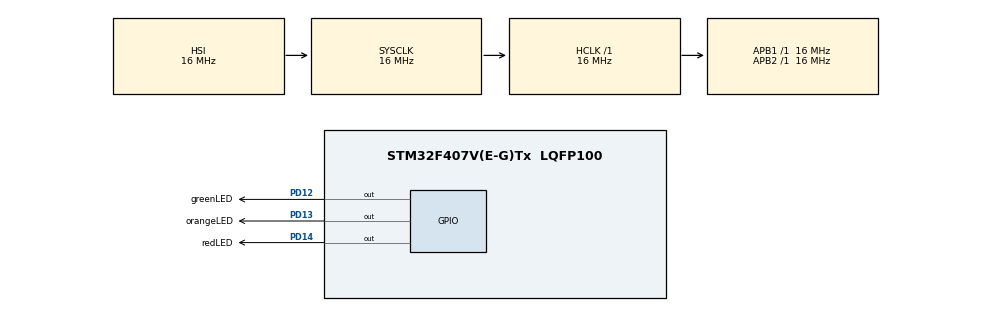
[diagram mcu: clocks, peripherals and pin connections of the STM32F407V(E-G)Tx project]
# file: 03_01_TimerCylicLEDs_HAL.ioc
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Mcu.Family=STM32F4
Mcu.Name=STM32F407V(E-G)Tx
Mcu.Package=LQFP100
NVIC.PriorityGroup=NVIC_PRIORITYGROUP_4
PD12.GPIO_Label=greenLED
PD12.Signal=GPIO_Output
PD13.GPIO_Label=orangeLED
PD13.Signal=GPIO_Output
PD14.GPIO_Label=redLED
PD14.Signal=GPIO_Output
ProjectManager.HeapSize=0x200
ProjectManager.StackSize=0x400
ProjectManager.TargetToolchain=STM32CubeIDE
RCC.AHBFreq_Value=16000000
RCC.APB1Freq_Value=16000000
RCC.APB2Freq_Value=16000000
RCC.CortexFreq_Value=16000000
RCC.HSE_VALUE=25000000
RCC.HSI_VALUE=16000000
RCC.LSE_VALUE=32768
RCC.SYSCLKFreq_VALUE=16000000
RCC.VCOOutputFreq_Value=192000000
TIM10.AutoReloadPreload=TIM_AUTORELOAD_PRELOAD_ENABLE
TIM10.Period=6000
TIM10.Prescaler=16-1
VP_TIM10_VS_ClockSourceINT.Mode=Enable_Timer
board=custom

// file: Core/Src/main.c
/* USER CODE BEGIN Header */
/**
  ******************************************************************************
  * @file           : main.c
  * @brief          : Main program body
  ******************************************************************************
  * @attention
  *
  * Copyright (c) 2024 STMicroelectronics.
  * All rights reserved.
  *
  * This software is licensed under terms that can be found in the LICENSE file
  * in the root directory of this software component.
  * If no LICENSE file comes with this software, it is provided AS-IS.
  *
  ******************************************************************************
  */
/* USER CODE END Header */
#include "main.h"

TIM_HandleTypeDef htim10;

void SystemClock_Config(void);
static void MX_GPIO_Init(void);
static void MX_TIM10_Init(void);
/* USER CODE BEGIN PFP */

void TimerReset(void);
int IsTimeUp(void);
void TimerInit(unsigned short first_durr) ;
/* USER CODE END PFP */

int main(void)
{

  /* USER CODE BEGIN 1 */
	uint8_t state =0;
  /* USER CODE END 1 */

  /* MCU Configuration--------------------------------------------------------*/

  /* Reset of all peripherals, Initializes the Flash interface and the Systick. */
  HAL_Init();

  /* Configure the system clock */
  SystemClock_Config();

  /* Initialize all configured peripherals */
  MX_GPIO_Init();
  MX_TIM10_Init();
  /* USER CODE BEGIN 2 */
  TimerInit(500);
  TimerReset();
  /* USER CODE END 2 */

  /* Infinite loop */
  /* USER CODE BEGIN WHILE */
  while (1)
  {
	  if(IsTimeUp())  //If the end of the durration for
	  {    //the current state was reached
	   TimerReset();

	   switch(state) //display the current state
	   {
	    case 0:
	    	HAL_GPIO_WritePin(greenLED_GPIO_Port, greenLED_Pin, 1);
	    	HAL_GPIO_WritePin(orangeLED_GPIO_Port, orangeLED_Pin, 0);
	    	HAL_GPIO_WritePin(redLED_GPIO_Port, redLED_Pin, 0);
	    	break;
	    case 1:
	    	HAL_GPIO_WritePin(greenLED_GPIO_Port, greenLED_Pin, 0);
	    	HAL_GPIO_WritePin(orangeLED_GPIO_Port, orangeLED_Pin, 1);
	    	HAL_GPIO_WritePin(redLED_GPIO_Port, redLED_Pin, 0);
	    	break;
	    case 2:
	    	HAL_GPIO_WritePin(greenLED_GPIO_Port, greenLED_Pin, 0);
	    	HAL_GPIO_WritePin(orangeLED_GPIO_Port, orangeLED_Pin, 0);
	    	HAL_GPIO_WritePin(redLED_GPIO_Port, redLED_Pin, 1);
	    	break;
	    break;
	   }

	   if ( ++state == 3 ) state=0;
	  }

    /* USER CODE END WHILE */

  }
}

void SystemClock_Config(void)
{
  RCC_OscInitTypeDef RCC_OscInitStruct = {0};
  RCC_ClkInitTypeDef RCC_ClkInitStruct = {0};

  /** Configure the main internal regulator output voltage
  */
  __HAL_RCC_PWR_CLK_ENABLE();
  __HAL_PWR_VOLTAGESCALING_CONFIG(PWR_REGULATOR_VOLTAGE_SCALE1);

  /** Initializes the RCC Oscillators according to the specified parameters
  * in the RCC_OscInitTypeDef structure.
  */
  RCC_OscInitStruct.OscillatorType = RCC_OSCILLATORTYPE_HSI;
  RCC_OscInitStruct.HSIState = RCC_HSI_ON;
  RCC_OscInitStruct.HSICalibrationValue = RCC_HSICALIBRATION_DEFAULT;
  RCC_OscInitStruct.PLL.PLLState = RCC_PLL_NONE;
  if (HAL_RCC_OscConfig(&RCC_OscInitStruct) != HAL_OK)
  {
    Error_Handler();
  }

  /** Initializes the CPU, AHB and APB buses clocks
  */
  RCC_ClkInitStruct.ClockType = RCC_CLOCKTYPE_HCLK|RCC_CLOCKTYPE_SYSCLK
                              |RCC_CLOCKTYPE_PCLK1|RCC_CLOCKTYPE_PCLK2;
  RCC_ClkInitStruct.SYSCLKSource = RCC_SYSCLKSOURCE_HSI;
  RCC_ClkInitStruct.AHBCLKDivider = RCC_SYSCLK_DIV1;
  RCC_ClkInitStruct.APB1CLKDivider = RCC_HCLK_DIV1;
  RCC_ClkInitStruct.APB2CLKDivider = RCC_HCLK_DIV1;

  if (HAL_RCC_ClockConfig(&RCC_ClkInitStruct, FLASH_LATENCY_0) != HAL_OK)
  {
    Error_Handler();
  }
}

static void MX_TIM10_Init(void)
{

  htim10.Instance = TIM10;
  htim10.Init.Prescaler = 16-1;
  htim10.Init.CounterMode = TIM_COUNTERMODE_UP;
  htim10.Init.Period = 6000;
  htim10.Init.ClockDivision = TIM_CLOCKDIVISION_DIV1;
  htim10.Init.AutoReloadPreload = TIM_AUTORELOAD_PRELOAD_ENABLE;
  if (HAL_TIM_Base_Init(&htim10) != HAL_OK)
  {
    Error_Handler();
  }

}

static void MX_GPIO_Init(void)
{
  GPIO_InitTypeDef GPIO_InitStruct = {0};

  /* GPIO Ports Clock Enable */
  __HAL_RCC_GPIOD_CLK_ENABLE();

  /*Configure GPIO pin Output Level */
  HAL_GPIO_WritePin(GPIOD, greenLED_Pin|orangeLED_Pin|redLED_Pin, GPIO_PIN_RESET);

  /*Configure GPIO pins : greenLED_Pin orangeLED_Pin redLED_Pin */
  GPIO_InitStruct.Pin = greenLED_Pin|orangeLED_Pin|redLED_Pin;
  GPIO_InitStruct.Mode = GPIO_MODE_OUTPUT_PP;
  GPIO_InitStruct.Pull = GPIO_NOPULL;
  GPIO_InitStruct.Speed = GPIO_SPEED_FREQ_LOW;
  HAL_GPIO_Init(GPIOD, &GPIO_InitStruct);

}

/* USER CODE BEGIN 4 */

void TimerReset()
{
    TIM10->EGR |= 0x0001; //Forces initial updating of the timer
    TIM10->SR = 0x0000;   //Clearing the status register
 // to prevent immеdiate transition
}
int IsTimeUp()
{
    return TIM10->SR & 0x0002;
}
void TimerInit(unsigned short first_durr)
{
 //Timer handling transition of the states
 TIM10->CCMR1 = 0x0000;  //Set as output (compare function еnabled)
 TIM10->PSC = 16800; //Set prescaler to 16800 (each tick is 0.1 millisec)
 TIM10->ARR = 60000; //Set auto-reload value to 60000 (close to maximum)
//Set comparator value to the durration for the first state ms->0.1ms count
 TIM10->CCR1 = first_durr;
 TIM10->CR1 |= 0x0081; //Enables the timer
}
/* USER CODE END 4 */

void Error_Handler(void)
{
  __disable_irq();
  while (1)
  {
  }
}
